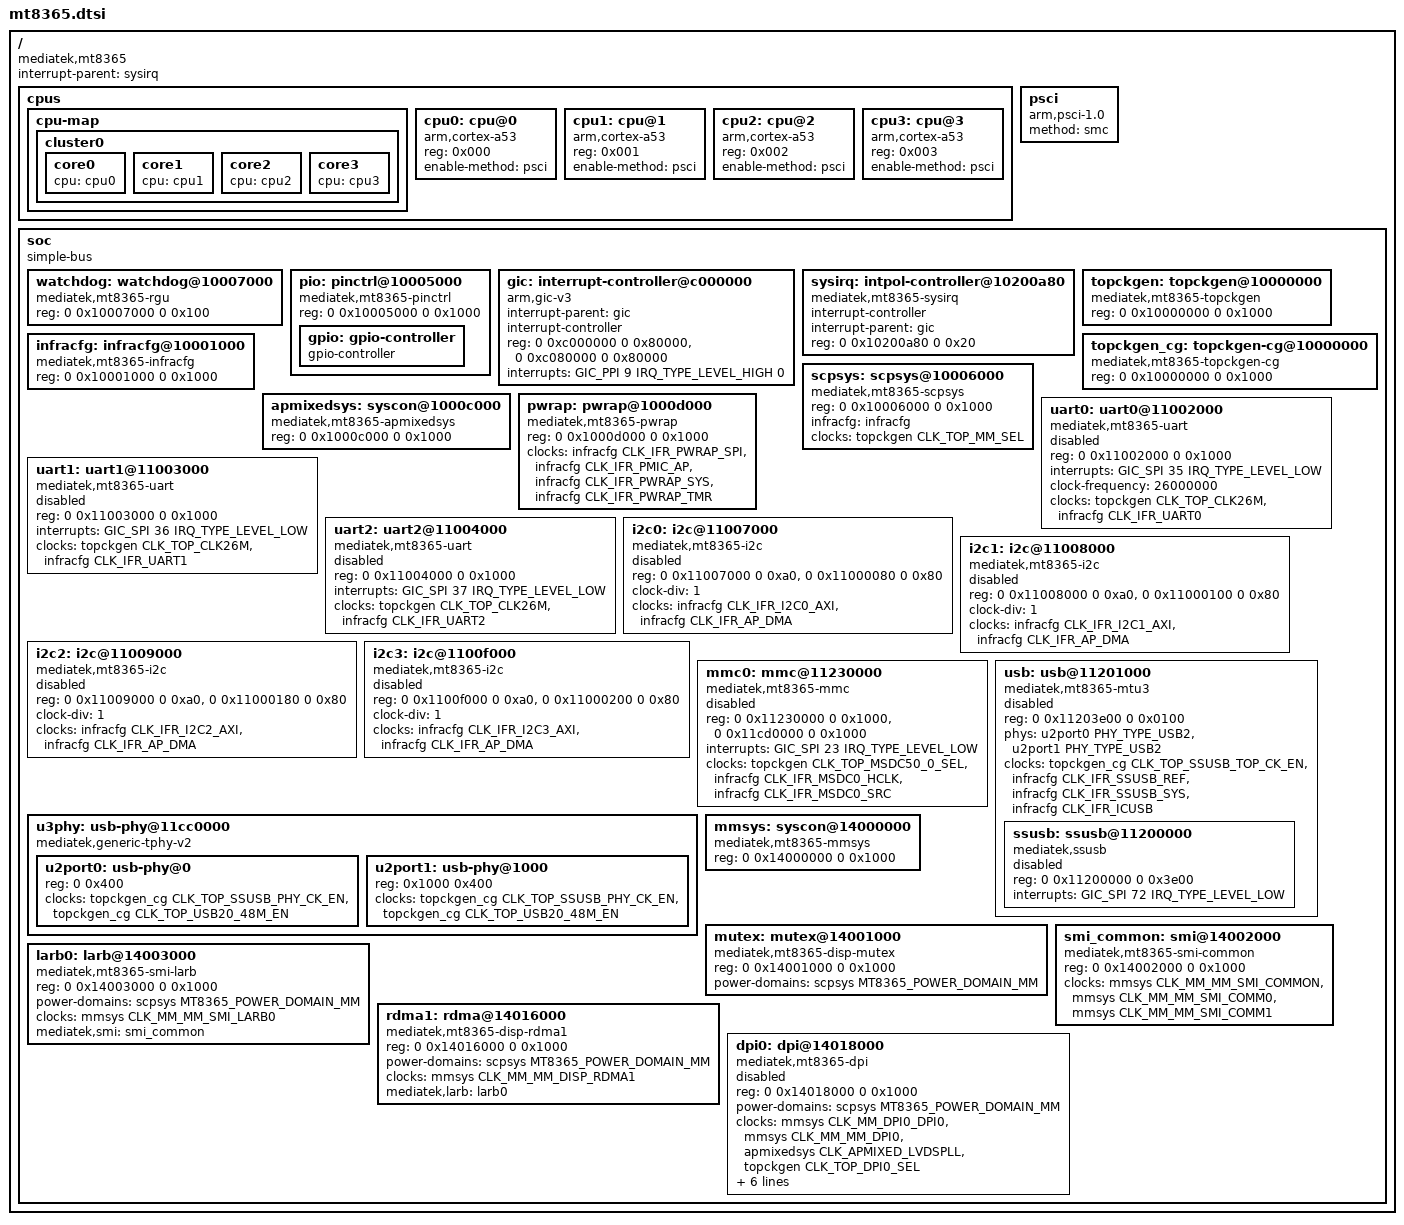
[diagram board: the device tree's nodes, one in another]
// SPDX-License-Identifier: (GPL-2.0 OR MIT)
/*
 * Copyright (C) 2021 MediaTek Inc.
 * Copyright (C) 2021 BayLibre, SAS
 * Author: Ben Ho <ben.ho@mediatek.com>
 *         Erin Lo <erin.lo@mediatek.com>
 *         Fabien Parent <fparent@baylibre.com>
 */

#include <dt-bindings/gpio/gpio.h>
#include <dt-bindings/clock/mt8365-clk.h>
#include <dt-bindings/interrupt-controller/irq.h>
#include <dt-bindings/interrupt-controller/arm-gic.h>
#include <dt-bindings/pinctrl/mt8365-pinfunc.h>
#include <dt-bindings/phy/phy.h>
#include <dt-bindings/power/mt8365-power.h>

/ {
	compatible = "mediatek,mt8365";
	interrupt-parent = <&sysirq>;
	#address-cells = <2>;
	#size-cells = <2>;

	cpus {
		#address-cells = <1>;
		#size-cells = <0>;

		cpu-map {
			cluster0 {
				core0 {
					cpu = <&cpu0>;
				};
				core1 {
					cpu = <&cpu1>;
				};
				core2 {
					cpu = <&cpu2>;
				};
				core3 {
					cpu = <&cpu3>;
				};
			};
		};

		cpu0: cpu@0 {
			device_type = "cpu";
			compatible = "arm,cortex-a53";
			reg = <0x000>;
			enable-method = "psci";
		};

		cpu1: cpu@1 {
			device_type = "cpu";
			compatible = "arm,cortex-a53";
			reg = <0x001>;
			enable-method = "psci";
		};

		cpu2: cpu@2 {
			device_type = "cpu";
			compatible = "arm,cortex-a53";
			reg = <0x002>;
			enable-method = "psci";
		};

		cpu3: cpu@3 {
			device_type = "cpu";
			compatible = "arm,cortex-a53";
			reg = <0x003>;
			enable-method = "psci";
		};
	};

	psci {
		compatible = "arm,psci-1.0";
		method = "smc";
	};

	soc {
		#address-cells = <2>;
		#size-cells = <2>;
		compatible = "simple-bus";
		ranges;

		watchdog: watchdog@10007000 {
			compatible = "mediatek,mt8365-rgu",
				     "mediatek,wdt";
			reg = <0 0x10007000 0 0x100>;
			#reset-cells = <1>;
		};

		pio: pinctrl@10005000 {
			compatible = "mediatek,mt8365-pinctrl";
			reg = <0 0x10005000 0 0x1000>;

			gpio: gpio-controller {
				gpio-controller;
				#gpio-cells = <2>;
			};
		};

		gic: interrupt-controller@c000000 {
			compatible = "arm,gic-v3";
			#interrupt-cells = <4>;
			interrupt-parent = <&gic>;
			interrupt-controller;
			reg = <0 0xc000000 0 0x80000>,
			      <0 0xc080000 0 0x80000>;

			interrupts = <GIC_PPI 9 IRQ_TYPE_LEVEL_HIGH 0>;
		};

		sysirq: intpol-controller@10200a80 {
			compatible = "mediatek,mt8365-sysirq",
				     "mediatek,mt6577-sysirq";
			interrupt-controller;
			#interrupt-cells = <3>;
			interrupt-parent = <&gic>;
			reg = <0 0x10200a80 0 0x20>;
		};

		topckgen: topckgen@10000000 {
			compatible = "mediatek,mt8365-topckgen", "syscon";
			reg = <0 0x10000000 0 0x1000>;
			#clock-cells = <1>;
		};

		topckgen_cg: topckgen-cg@10000000 {
			compatible = "mediatek,mt8365-topckgen-cg", "syscon";
			reg = <0 0x10000000 0 0x1000>;
			#clock-cells = <1>;
		};

		infracfg: infracfg@10001000 {
			compatible = "mediatek,mt8365-infracfg", "syscon";
			reg = <0 0x10001000 0 0x1000>;
			#clock-cells = <1>;
		};

		scpsys: scpsys@10006000 {
			compatible = "mediatek,mt8365-scpsys";
			#power-domain-cells = <1>;
			reg = <0 0x10006000 0 0x1000>;
			infracfg = <&infracfg>;
			clocks = <&topckgen CLK_TOP_MM_SEL>;
			clock-names = "mm";
		};

		apmixedsys: syscon@1000c000 {
			compatible = "mediatek,mt8365-apmixedsys", "syscon";
			reg = <0 0x1000c000 0 0x1000>;
			#clock-cells = <1>;
		};

		pwrap: pwrap@1000d000 {
			compatible = "mediatek,mt8365-pwrap";
			reg = <0 0x1000d000 0 0x1000>;
			clocks = <&infracfg CLK_IFR_PWRAP_SPI>,
				 <&infracfg CLK_IFR_PMIC_AP>,
				 <&infracfg CLK_IFR_PWRAP_SYS>,
				 <&infracfg CLK_IFR_PWRAP_TMR>;
			clock-names = "spi", "wrap", "wrap_sys", "wrap_tmr";
		};

		uart0: uart0@11002000 {
			compatible = "mediatek,mt8365-uart",
				     "mediatek,hsuart";
			reg = <0 0x11002000 0 0x1000>;
			interrupts = <GIC_SPI 35 IRQ_TYPE_LEVEL_LOW>;
			clock-frequency = <26000000>;
			clocks = <&topckgen CLK_TOP_CLK26M>, <&infracfg CLK_IFR_UART0>;
			clock-names = "baud", "bus";
			status = "disabled";
		};

		uart1: uart1@11003000 {
			compatible = "mediatek,mt8365-uart",
				     "mediatek,hsuart";
			reg = <0 0x11003000 0 0x1000>;
			interrupts = <GIC_SPI 36 IRQ_TYPE_LEVEL_LOW>;
			clocks = <&topckgen CLK_TOP_CLK26M>, <&infracfg CLK_IFR_UART1>;
			clock-names = "baud", "bus";
			status = "disabled";
		};

		uart2: uart2@11004000 {
			compatible = "mediatek,mt8365-uart",
				     "mediatek,hsuart";
			reg = <0 0x11004000 0 0x1000>;
			interrupts = <GIC_SPI 37 IRQ_TYPE_LEVEL_LOW>;
			clocks = <&topckgen CLK_TOP_CLK26M>, <&infracfg CLK_IFR_UART2>;
			clock-names = "baud", "bus";
			status = "disabled";
		};

		i2c0: i2c@11007000 {
			compatible = "mediatek,mt8365-i2c";
			reg = <0 0x11007000 0 0xa0>,
			      <0 0x11000080 0 0x80>;
			clock-div = <1>;
			clocks = <&infracfg CLK_IFR_I2C0_AXI>,
				 <&infracfg CLK_IFR_AP_DMA>;
			clock-names = "main", "dma";
			#address-cells = <1>;
			#size-cells = <0>;
			status = "disabled";
		};

		i2c1: i2c@11008000 {
			compatible = "mediatek,mt8365-i2c";
			reg = <0 0x11008000 0 0xa0>,
			      <0 0x11000100 0 0x80>;
			clock-div = <1>;
			clocks = <&infracfg CLK_IFR_I2C1_AXI>,
				 <&infracfg CLK_IFR_AP_DMA>;
			clock-names = "main", "dma";
			#address-cells = <1>;
			#size-cells = <0>;
			status = "disabled";
		};

		i2c2: i2c@11009000 {
			compatible = "mediatek,mt8365-i2c";
			reg = <0 0x11009000 0 0xa0>,
			      <0 0x11000180 0 0x80>;
			clock-div = <1>;
			clocks = <&infracfg CLK_IFR_I2C2_AXI>,
				 <&infracfg CLK_IFR_AP_DMA>;
			clock-names = "main", "dma";
			#address-cells = <1>;
			#size-cells = <0>;
			status = "disabled";
		};

		i2c3: i2c@1100f000 {
			compatible = "mediatek,mt8365-i2c";
			reg = <0 0x1100f000 0 0xa0>,
			      <0 0x11000200 0 0x80>;
			clock-div = <1>;
			clocks = <&infracfg CLK_IFR_I2C3_AXI>,
				 <&infracfg CLK_IFR_AP_DMA>;
			clock-names = "main", "dma";
			#address-cells = <1>;
			#size-cells = <0>;
			status = "disabled";
		};

		mmc0: mmc@11230000 {
			compatible = "mediatek,mt8365-mmc", "mediatek,mt8183-mmc";
			reg = <0 0x11230000 0 0x1000>,
			      <0 0x11cd0000 0 0x1000>;
			interrupts = <GIC_SPI 23 IRQ_TYPE_LEVEL_LOW>;
			clocks = <&topckgen CLK_TOP_MSDC50_0_SEL>,
				 <&infracfg CLK_IFR_MSDC0_HCLK>,
				 <&infracfg CLK_IFR_MSDC0_SRC>;
			clock-names = "source", "hclk", "source_cg";
			status = "disabled";
		};

		u3phy: usb-phy@11cc0000 {
			compatible = "mediatek,generic-tphy-v2";
			#address-cells = <1>;
			#size-cells = <1>;
			ranges = <0 0 0x11cc0000 0x2000>;
			status = "okay";

			u2port0: usb-phy@0 {
				reg = <0 0x400>;
				clocks = <&topckgen_cg CLK_TOP_SSUSB_PHY_CK_EN>,
					 <&topckgen_cg CLK_TOP_USB20_48M_EN>;
				clock-names = "ref", "da_ref";
				#phy-cells = <1>;
				status = "okay";
			};

			u2port1: usb-phy@1000 {
				reg = <0x1000 0x400>;
				clocks = <&topckgen_cg CLK_TOP_SSUSB_PHY_CK_EN>,
					 <&topckgen_cg CLK_TOP_USB20_48M_EN>;
				clock-names = "ref", "da_ref";
				#phy-cells = <1>;
				status = "okay";
			};
		};

		usb: usb@11201000 {
			compatible ="mediatek,mt8365-mtu3", "mediatek,mtu3";
			reg = <0 0x11203e00 0 0x0100>;
			reg-names = "ippc";
			phys = <&u2port0 PHY_TYPE_USB2>,
			       <&u2port1 PHY_TYPE_USB2>;
			clocks = <&topckgen_cg CLK_TOP_SSUSB_TOP_CK_EN>,
				 <&infracfg CLK_IFR_SSUSB_REF>,
				 <&infracfg CLK_IFR_SSUSB_SYS>,
				 <&infracfg CLK_IFR_ICUSB>;
			clock-names = "sys_ck", "ref_ck", "mcu_ck",
				      "dma_ck";
			#address-cells = <2>;
			#size-cells = <2>;
			ranges;
			status = "disabled";

			ssusb: ssusb@11200000 {
				compatible = "mediatek,ssusb";
				reg = <0 0x11200000 0 0x3e00>;
				reg-names = "mac";
				interrupts = <GIC_SPI 72 IRQ_TYPE_LEVEL_LOW>;
				status = "disabled";
			};
		};

		mmsys: syscon@14000000 {
			compatible = "mediatek,mt8365-mmsys", "syscon";
			reg = <0 0x14000000 0 0x1000>;
			#clock-cells = <1>;
		};

		mutex: mutex@14001000 {
			compatible =  "mediatek,mt8365-disp-mutex";
			reg = <0 0x14001000 0 0x1000>;
			power-domains = <&scpsys MT8365_POWER_DOMAIN_MM>;
		};

		smi_common: smi@14002000 {
			compatible = "mediatek,mt8365-smi-common";
			reg = <0 0x14002000 0 0x1000>;
			clocks = <&mmsys CLK_MM_MM_SMI_COMMON>,
				 <&mmsys CLK_MM_MM_SMI_COMM0>,
				 <&mmsys CLK_MM_MM_SMI_COMM1>;
			clock-names = "common", "comm0", "comm1";
		};

		larb0: larb@14003000 {
			compatible = "mediatek,mt8365-smi-larb";
			reg = <0 0x14003000 0 0x1000>;
			power-domains = <&scpsys MT8365_POWER_DOMAIN_MM>;
			clocks = <&mmsys CLK_MM_MM_SMI_LARB0>;
			mediatek,smi = <&smi_common>;
		};

		rdma1: rdma@14016000 {
			compatible = "mediatek,mt8365-disp-rdma1";
			reg = <0 0x14016000 0 0x1000>;
			power-domains = <&scpsys MT8365_POWER_DOMAIN_MM>;
			clocks = <&mmsys CLK_MM_MM_DISP_RDMA1>;
			mediatek,larb = <&larb0>;
		};

		dpi0: dpi@14018000 {
			compatible = "mediatek,mt8365-dpi";
			reg = <0 0x14018000 0 0x1000>;
			power-domains = <&scpsys MT8365_POWER_DOMAIN_MM>;
			clocks = <&mmsys CLK_MM_DPI0_DPI0>,
				 <&mmsys CLK_MM_MM_DPI0>,
				 <&apmixedsys CLK_APMIXED_LVDSPLL>,
				 <&topckgen CLK_TOP_DPI0_SEL>;
			clock-names = "dpi_sel", "engine", "pll", "pixel";
			assigned-clocks = <&topckgen CLK_TOP_DPI0_SEL>;
			assigned-clock-parents = <&topckgen CLK_TOP_LVDSPLL_D4>;
			mediatek,rdma = <&rdma1>;
			mediatek,mutex = <&mutex>;
			mediatek,mmsys = <&mmsys>;
			status = "disabled";
		};
	};
};
